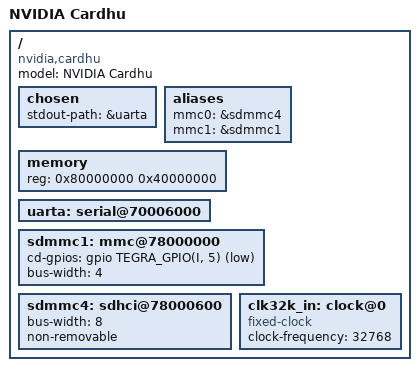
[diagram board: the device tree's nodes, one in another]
/dts-v1/;

#include "tegra30.dtsi"

/ {
	model = "NVIDIA Cardhu";
	compatible = "nvidia,cardhu", "nvidia,tegra30";

	chosen {
		stdout-path = &uarta;
	};

	aliases {
		mmc0 = &sdmmc4; /* eMMC */
		mmc1 = &sdmmc1; /* uSD slot */
	};

	memory {
		device_type = "memory";
		reg = <0x80000000 0x40000000>;
	};

	uarta: serial@70006000 {
		status = "okay";
	};

	sdmmc1: mmc@78000000 {
		status = "okay";
		cd-gpios = <&gpio TEGRA_GPIO(I, 5) GPIO_ACTIVE_LOW>;
		bus-width = <4>;
	};

	sdmmc4: sdhci@78000600 {
		status = "okay";
		bus-width = <8>;
		non-removable;
	};

	clk32k_in: clock@0 {
		compatible = "fixed-clock";
		#clock-cells = <0>;
		clock-frequency = <32768>;
	};
};
